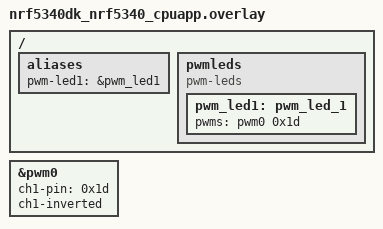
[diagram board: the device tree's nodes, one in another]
/*
 * Copyright (c) 2021 Nordic Semiconductor ASA
 *
 * SPDX-License-Identifier: LicenseRef-Nordic-5-Clause
 */

/ {
	/*
	* By default, PWM module is only configured for led0 (LED1 on the board).
	* The lighting-app, however, uses LED2 to show the state of the lighting,
	* including its brightness level.
	*/
	aliases {
		pwm-led1 = &pwm_led1;
	};

	pwmleds {
		compatible = "pwm-leds";
		pwm_led1: pwm_led_1 {
			pwms = < &pwm0 0x1d >;
		};
	};

};

&pwm0 {
	/delete-property/ ch0-pin;
	/delete-property/ ch0-inverted;
	ch1-pin = < 0x1d >;
	ch1-inverted;
};
